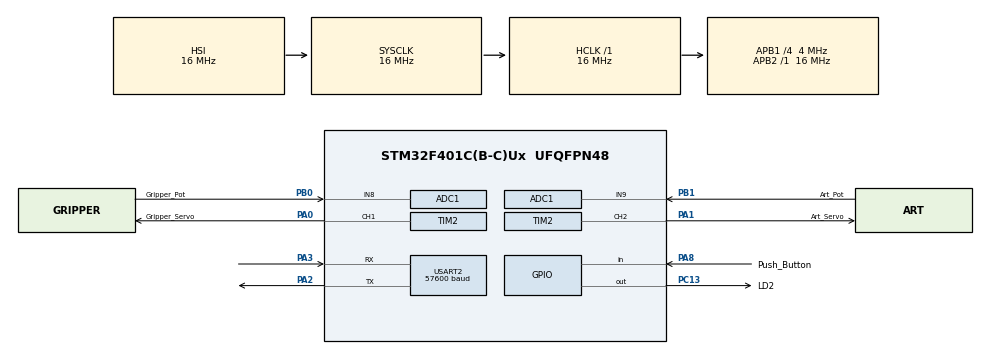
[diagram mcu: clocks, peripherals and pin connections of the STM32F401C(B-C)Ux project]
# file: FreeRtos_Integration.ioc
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ADC1.Channel-0\#ChannelRegularConversion=ADC_CHANNEL_8
ADC1.Channel-1\#ChannelRegularConversion=ADC_CHANNEL_9
ADC1.ContinuousConvMode=ENABLE
ADC1.NbrOfConversion=2
ADC1.NbrOfConversionFlag=1
ADC1.Rank-0\#ChannelRegularConversion=1
ADC1.Rank-1\#ChannelRegularConversion=2
ADC1.SamplingTime-0\#ChannelRegularConversion=ADC_SAMPLETIME_480CYCLES
ADC1.SamplingTime-1\#ChannelRegularConversion=ADC_SAMPLETIME_480CYCLES
ADC1.ScanConvMode=ENABLE
ADC1.master=1
Dma.ADC1.0.Direction=DMA_PERIPH_TO_MEMORY
Dma.ADC1.0.FIFOMode=DMA_FIFOMODE_DISABLE
Dma.ADC1.0.Instance=DMA2_Stream0
Dma.ADC1.0.MemDataAlignment=DMA_MDATAALIGN_HALFWORD
Dma.ADC1.0.MemInc=DMA_MINC_ENABLE
Dma.ADC1.0.Mode=DMA_NORMAL
Dma.ADC1.0.PeriphDataAlignment=DMA_PDATAALIGN_HALFWORD
Dma.ADC1.0.PeriphInc=DMA_PINC_DISABLE
Dma.ADC1.0.Priority=DMA_PRIORITY_LOW
Dma.Request0=ADC1
Dma.Request1=USART2_RX
Dma.Request2=USART2_TX
Dma.USART2_RX.1.Direction=DMA_PERIPH_TO_MEMORY
Dma.USART2_RX.1.FIFOMode=DMA_FIFOMODE_DISABLE
Dma.USART2_RX.1.Instance=DMA1_Stream5
Dma.USART2_RX.1.MemDataAlignment=DMA_MDATAALIGN_BYTE
Dma.USART2_RX.1.MemInc=DMA_MINC_ENABLE
Dma.USART2_RX.1.Mode=DMA_NORMAL
Dma.USART2_RX.1.PeriphDataAlignment=DMA_PDATAALIGN_BYTE
Dma.USART2_RX.1.PeriphInc=DMA_PINC_DISABLE
Dma.USART2_RX.1.Priority=DMA_PRIORITY_LOW
Dma.USART2_TX.2.Direction=DMA_MEMORY_TO_PERIPH
Dma.USART2_TX.2.FIFOMode=DMA_FIFOMODE_DISABLE
Dma.USART2_TX.2.Instance=DMA1_Stream6
Dma.USART2_TX.2.MemDataAlignment=DMA_MDATAALIGN_BYTE
Dma.USART2_TX.2.MemInc=DMA_MINC_ENABLE
Dma.USART2_TX.2.Mode=DMA_NORMAL
Dma.USART2_TX.2.PeriphDataAlignment=DMA_PDATAALIGN_BYTE
Dma.USART2_TX.2.PeriphInc=DMA_PINC_DISABLE
Dma.USART2_TX.2.Priority=DMA_PRIORITY_LOW
FREERTOS.Tasks01=TaskADC,24,128,StartTaskADC,Default,NULL,Dynamic,NULL,NULL;GripperOpenTask,25,128,StartGripperOpenTask,Default,NULL,Dynamic,NULL,NULL;GripperClose,26,128,StartGripperCloseTask,Default,NULL,Dynamic,NULL,NULL;GripperGoToTask,27,128,StartGripperGoToTask,Default,NULL,Dynamic,NULL,NULL;TaskRosserial,40,128,StartTaskRosserial,Default,NULL,Dynamic,NULL,NULL;ButtonTask,8,128,StartButtonTask,Default,NULL,Dynamic,NULL,NULL;ArtUpTask,28,128,StartArtUpTask,Default,NULL,Dynamic,NULL,NULL;ArtDownTask,29,128,StartArtDownTask,Default,NULL,Dynamic,NULL,NULL;ArtGoToTask,30,128,StartArtGoToTask,Default,NULL,Dynamic,NULL,NULL
FREERTOS.configUSE_NEWLIB_REENTRANT=1
Mcu.Family=STM32F4
Mcu.Name=STM32F401C(B-C)Ux
Mcu.Package=UFQFPN48
NVIC.DMA1_Stream5_IRQn=true\:5\:0\:false\:false\:true\:true\:false\:true\:true
NVIC.DMA1_Stream6_IRQn=true\:5\:0\:false\:false\:true\:true\:false\:true\:true
NVIC.DMA2_Stream0_IRQn=true\:5\:0\:false\:false\:true\:true\:false\:true\:true
NVIC.PriorityGroup=NVIC_PRIORITYGROUP_4
NVIC.TIM5_IRQn=true\:15\:0\:false\:false\:true\:false\:false\:true\:true
NVIC.TimeBase=TIM5_IRQn
NVIC.TimeBaseIP=TIM5
NVIC.USART2_IRQn=true\:5\:0\:false\:false\:true\:true\:true\:true\:true
PA0-WKUP.GPIO_Label=Gripper_Servo
PA0-WKUP.Signal=S_TIM2_CH1_ETR
PA1.GPIO_Label=Art_Servo
PA1.Signal=S_TIM2_CH2
PA2.Mode=Asynchronous
PA2.Signal=USART2_TX
PA3.Mode=Asynchronous
PA3.Signal=USART2_RX
PA8.GPIO_Label=Push_Button
PA8.Signal=GPIO_Input
PB0.GPIO_Label=Gripper_Pot
PB0.Signal=ADCx_IN8
PB1.GPIO_Label=Art_Pot
PB1.Signal=ADCx_IN9
PC13-ANTI_TAMP.GPIO_Label=LD2
PC13-ANTI_TAMP.Signal=GPIO_Output
ProjectManager.HeapSize=0x200
ProjectManager.StackSize=0x400
ProjectManager.TargetToolchain=STM32CubeIDE
RCC.AHBFreq_Value=16000000
RCC.APB1CLKDivider=RCC_HCLK_DIV4
RCC.APB1Freq_Value=4000000
RCC.APB1TimFreq_Value=8000000
RCC.APB2Freq_Value=16000000
RCC.CortexFreq_Value=16000000
RCC.HSE_VALUE=25000000
RCC.HSI_VALUE=16000000
RCC.LSE_VALUE=32768
RCC.SYSCLKFreq_VALUE=16000000
RCC.VCOOutputFreq_Value=192000000
SH.ADCx_IN8.0=ADC1_IN8,IN8
SH.ADCx_IN9.0=ADC1_IN9,IN9
SH.S_TIM2_CH1_ETR.0=TIM2_CH1,PWM Generation1 CH1
SH.S_TIM2_CH2.0=TIM2_CH2,PWM Generation2 CH2
TIM2.Channel-PWM\ Generation1\ CH1=TIM_CHANNEL_1
TIM2.Channel-PWM\ Generation2\ CH2=TIM_CHANNEL_2
TIM2.Period=2499
TIM2.Prescaler=64
USART2.BaudRate=57600
USART2.VirtualMode=VM_ASYNC
VP_FREERTOS_VS_CMSIS_V2.Mode=CMSIS_V2
VP_SYS_VS_tim5.Mode=TIM5
VP_TIM2_VS_ClockSourceINT.Mode=Internal
board=custom

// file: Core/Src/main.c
/* USER CODE BEGIN Header */
/**
  ******************************************************************************
  * @file           : main.c
  * @brief          : Main program body
  ******************************************************************************
  * @attention
  *
  * Copyright (c) 2023 STMicroelectronics.
  * All rights reserved.
  *
  * This software is licensed under terms that can be found in the LICENSE file
  * in the root directory of this software component.
  * If no LICENSE file comes with this software, it is provided AS-IS.
  *
  ******************************************************************************
  */
/* USER CODE END Header */
#include "main.h"
#include "cmsis_os.h"

/* USER CODE BEGIN Includes */
#include "mainpp.h"
/* USER CODE END Includes */

/* USER CODE BEGIN PD */
#define GRIPPER_OPENED_ANG = 0;
#define GRIPPER_CLOSED_ANG = 105;
#define ART_DOWN_ANG = 0;
#define ART_UP_ANG = 90;
/* USER CODE END PD */

ADC_HandleTypeDef hadc1;
DMA_HandleTypeDef hdma_adc1;

TIM_HandleTypeDef htim2;

UART_HandleTypeDef huart2;
DMA_HandleTypeDef hdma_usart2_rx;
DMA_HandleTypeDef hdma_usart2_tx;

/* Definitions for TaskADC */
osThreadId_t TaskADCHandle;
const osThreadAttr_t TaskADC_attributes = {
  .name = "TaskADC",
  .stack_size = 128 * 4,
  .priority = (osPriority_t) osPriorityAboveNormal,
};
/* Definitions for GripperOpenTask */
osThreadId_t GripperOpenTaskHandle;
const osThreadAttr_t GripperOpenTask_attributes = {
  .name = "GripperOpenTask",
  .stack_size = 128 * 4,
  .priority = (osPriority_t) osPriorityNormal,
};
/* Definitions for GripperClose */
osThreadId_t GripperCloseHandle;
const osThreadAttr_t GripperClose_attributes = {
  .name = "GripperClose",
  .stack_size = 128 * 4,
  .priority = (osPriority_t) osPriorityNormal,
};
/* Definitions for GripperGoToTask */
osThreadId_t GripperGoToTaskHandle;
const osThreadAttr_t GripperGoToTask_attributes = {
  .name = "GripperGoToTask",
  .stack_size = 128 * 4,
  .priority = (osPriority_t) osPriorityNormal,
};
/* Definitions for TaskRosserial */
osThreadId_t TaskRosserialHandle;
const osThreadAttr_t TaskRosserial_attributes = {
  .name = "TaskRosserial",
  .stack_size = 128 * 4,
  .priority = (osPriority_t) osPriorityHigh,
};
/* USER CODE BEGIN PV */
// ADC Variables & constants
int adc1, adc2;
int ang[2];
volatile uint16_t adc_result[2];
const int adc_channel_count = sizeof(adc_result) / sizeof(adc_result[0]);

// Flags
int gripper_instruction_flag = 0;
int art_instruction_flag = 0;
int gripper_ang_response = 0;
int art_ang_response = 0;
int button_pressed = 0;
int emergency_stop = 0;

// Servo constants

/* USER CODE END PV */

void SystemClock_Config(void);
static void MX_GPIO_Init(void);
static void MX_DMA_Init(void);
static void MX_ADC1_Init(void);
static void MX_TIM2_Init(void);
static void MX_USART2_UART_Init(void);
void StartTaskADC(void *argument);
void StartGripperOpenTask(void *argument);
void StartGripperClose(void *argument);
void StartGripperGoToTask(void *argument);
void StartTaskRosserial(void *argument);

int main(void)
{

  /* MCU Configuration--------------------------------------------------------*/

  /* Reset of all peripherals, Initializes the Flash interface and the Systick. */
  HAL_Init();

  /* Configure the system clock */
  SystemClock_Config();

  /* Initialize all configured peripherals */
  MX_GPIO_Init();
  MX_DMA_Init();
  MX_ADC1_Init();
  MX_TIM2_Init();
  MX_USART2_UART_Init();
  /* USER CODE BEGIN 2 */
  HAL_TIM_PWM_Start(&htim2, TIM_CHANNEL_1);
  HAL_TIM_PWM_Start(&htim2, TIM_CHANNEL_2);
  setup();
  TIM2->CCR1 = 60;
  TIM2->CCR2 = 60;
  /* USER CODE END 2 */

  /* Init scheduler */
  osKernelInitialize();

  /* Create the thread(s) */
  /* creation of TaskADC */
  TaskADCHandle = osThreadNew(StartTaskADC, NULL, &TaskADC_attributes);

  /* creation of GripperOpenTask */
  GripperOpenTaskHandle = osThreadNew(StartGripperOpenTask, NULL, &GripperOpenTask_attributes);

  /* creation of GripperClose */
  GripperCloseHandle = osThreadNew(StartGripperClose, NULL, &GripperClose_attributes);

  /* creation of GripperGoToTask */
  GripperGoToTaskHandle = osThreadNew(StartGripperGoToTask, NULL, &GripperGoToTask_attributes);

  /* creation of TaskRosserial */
  TaskRosserialHandle = osThreadNew(StartTaskRosserial, NULL, &TaskRosserial_attributes);

  /* Start scheduler */
  osKernelStart();
  /* We should never get here as control is now taken by the scheduler */
  /* Infinite loop */
  while (1)
  {

  }
}

void SystemClock_Config(void)
{
  RCC_OscInitTypeDef RCC_OscInitStruct = {0};
  RCC_ClkInitTypeDef RCC_ClkInitStruct = {0};

  /** Configure the main internal regulator output voltage
  */
  __HAL_RCC_PWR_CLK_ENABLE();
  __HAL_PWR_VOLTAGESCALING_CONFIG(PWR_REGULATOR_VOLTAGE_SCALE2);

  /** Initializes the RCC Oscillators according to the specified parameters
  * in the RCC_OscInitTypeDef structure.
  */
  RCC_OscInitStruct.OscillatorType = RCC_OSCILLATORTYPE_HSI;
  RCC_OscInitStruct.HSIState = RCC_HSI_ON;
  RCC_OscInitStruct.HSICalibrationValue = RCC_HSICALIBRATION_DEFAULT;
  RCC_OscInitStruct.PLL.PLLState = RCC_PLL_NONE;
  if (HAL_RCC_OscConfig(&RCC_OscInitStruct) != HAL_OK)
  {
    Error_Handler();
  }

  /** Initializes the CPU, AHB and APB buses clocks
  */
  RCC_ClkInitStruct.ClockType = RCC_CLOCKTYPE_HCLK|RCC_CLOCKTYPE_SYSCLK
                              |RCC_CLOCKTYPE_PCLK1|RCC_CLOCKTYPE_PCLK2;
  RCC_ClkInitStruct.SYSCLKSource = RCC_SYSCLKSOURCE_HSI;
  RCC_ClkInitStruct.AHBCLKDivider = RCC_SYSCLK_DIV1;
  RCC_ClkInitStruct.APB1CLKDivider = RCC_HCLK_DIV4;
  RCC_ClkInitStruct.APB2CLKDivider = RCC_HCLK_DIV1;

  if (HAL_RCC_ClockConfig(&RCC_ClkInitStruct, FLASH_LATENCY_0) != HAL_OK)
  {
    Error_Handler();
  }
}

static void MX_ADC1_Init(void)
{

  ADC_ChannelConfTypeDef sConfig = {0};

  /** Configure the global features of the ADC (Clock, Resolution, Data Alignment and number of conversion)
  */
  hadc1.Instance = ADC1;
  hadc1.Init.ClockPrescaler = ADC_CLOCK_SYNC_PCLK_DIV2;
  hadc1.Init.Resolution = ADC_RESOLUTION_12B;
  hadc1.Init.ScanConvMode = ENABLE;
  hadc1.Init.ContinuousConvMode = ENABLE;
  hadc1.Init.DiscontinuousConvMode = DISABLE;
  hadc1.Init.ExternalTrigConvEdge = ADC_EXTERNALTRIGCONVEDGE_NONE;
  hadc1.Init.ExternalTrigConv = ADC_SOFTWARE_START;
  hadc1.Init.DataAlign = ADC_DATAALIGN_RIGHT;
  hadc1.Init.NbrOfConversion = 2;
  hadc1.Init.DMAContinuousRequests = DISABLE;
  hadc1.Init.EOCSelection = ADC_EOC_SINGLE_CONV;
  if (HAL_ADC_Init(&hadc1) != HAL_OK)
  {
    Error_Handler();
  }

  /** Configure for the selected ADC regular channel its corresponding rank in the sequencer and its sample time.
  */
  sConfig.Channel = ADC_CHANNEL_8;
  sConfig.Rank = 1;
  sConfig.SamplingTime = ADC_SAMPLETIME_480CYCLES;
  if (HAL_ADC_ConfigChannel(&hadc1, &sConfig) != HAL_OK)
  {
    Error_Handler();
  }

  /** Configure for the selected ADC regular channel its corresponding rank in the sequencer and its sample time.
  */
  sConfig.Channel = ADC_CHANNEL_9;
  sConfig.Rank = 2;
  if (HAL_ADC_ConfigChannel(&hadc1, &sConfig) != HAL_OK)
  {
    Error_Handler();
  }

}

static void MX_TIM2_Init(void)
{

  TIM_ClockConfigTypeDef sClockSourceConfig = {0};
  TIM_MasterConfigTypeDef sMasterConfig = {0};
  TIM_OC_InitTypeDef sConfigOC = {0};

  htim2.Instance = TIM2;
  htim2.Init.Prescaler = 64;
  htim2.Init.CounterMode = TIM_COUNTERMODE_UP;
  htim2.Init.Period = 2499;
  htim2.Init.ClockDivision = TIM_CLOCKDIVISION_DIV1;
  htim2.Init.AutoReloadPreload = TIM_AUTORELOAD_PRELOAD_DISABLE;
  if (HAL_TIM_Base_Init(&htim2) != HAL_OK)
  {
    Error_Handler();
  }
  sClockSourceConfig.ClockSource = TIM_CLOCKSOURCE_INTERNAL;
  if (HAL_TIM_ConfigClockSource(&htim2, &sClockSourceConfig) != HAL_OK)
  {
    Error_Handler();
  }
  if (HAL_TIM_PWM_Init(&htim2) != HAL_OK)
  {
    Error_Handler();
  }
  sMasterConfig.MasterOutputTrigger = TIM_TRGO_RESET;
  sMasterConfig.MasterSlaveMode = TIM_MASTERSLAVEMODE_DISABLE;
  if (HAL_TIMEx_MasterConfigSynchronization(&htim2, &sMasterConfig) != HAL_OK)
  {
    Error_Handler();
  }
  sConfigOC.OCMode = TIM_OCMODE_PWM1;
  sConfigOC.Pulse = 0;
  sConfigOC.OCPolarity = TIM_OCPOLARITY_HIGH;
  sConfigOC.OCFastMode = TIM_OCFAST_DISABLE;
  if (HAL_TIM_PWM_ConfigChannel(&htim2, &sConfigOC, TIM_CHANNEL_1) != HAL_OK)
  {
    Error_Handler();
  }
  if (HAL_TIM_PWM_ConfigChannel(&htim2, &sConfigOC, TIM_CHANNEL_2) != HAL_OK)
  {
    Error_Handler();
  }
  HAL_TIM_MspPostInit(&htim2);

}

static void MX_USART2_UART_Init(void)
{

  huart2.Instance = USART2;
  huart2.Init.BaudRate = 57600;
  huart2.Init.WordLength = UART_WORDLENGTH_8B;
  huart2.Init.StopBits = UART_STOPBITS_1;
  huart2.Init.Parity = UART_PARITY_NONE;
  huart2.Init.Mode = UART_MODE_TX_RX;
  huart2.Init.HwFlowCtl = UART_HWCONTROL_NONE;
  huart2.Init.OverSampling = UART_OVERSAMPLING_16;
  if (HAL_UART_Init(&huart2) != HAL_OK)
  {
    Error_Handler();
  }

}

static void MX_DMA_Init(void)
{

  /* DMA controller clock enable */
  __HAL_RCC_DMA2_CLK_ENABLE();
  __HAL_RCC_DMA1_CLK_ENABLE();

  /* DMA interrupt init */
  /* DMA1_Stream5_IRQn interrupt configuration */
  HAL_NVIC_SetPriority(DMA1_Stream5_IRQn, 5, 0);
  HAL_NVIC_EnableIRQ(DMA1_Stream5_IRQn);
  /* DMA1_Stream6_IRQn interrupt configuration */
  HAL_NVIC_SetPriority(DMA1_Stream6_IRQn, 5, 0);
  HAL_NVIC_EnableIRQ(DMA1_Stream6_IRQn);
  /* DMA2_Stream0_IRQn interrupt configuration */
  HAL_NVIC_SetPriority(DMA2_Stream0_IRQn, 5, 0);
  HAL_NVIC_EnableIRQ(DMA2_Stream0_IRQn);

}

static void MX_GPIO_Init(void)
{
  GPIO_InitTypeDef GPIO_InitStruct = {0};

  /* GPIO Ports Clock Enable */
  __HAL_RCC_GPIOC_CLK_ENABLE();
  __HAL_RCC_GPIOA_CLK_ENABLE();
  __HAL_RCC_GPIOB_CLK_ENABLE();

  /*Configure GPIO pin Output Level */
  HAL_GPIO_WritePin(LD2_GPIO_Port, LD2_Pin, GPIO_PIN_RESET);

  /*Configure GPIO pin : LD2_Pin */
  GPIO_InitStruct.Pin = LD2_Pin;
  GPIO_InitStruct.Mode = GPIO_MODE_OUTPUT_PP;
  GPIO_InitStruct.Pull = GPIO_NOPULL;
  GPIO_InitStruct.Speed = GPIO_SPEED_FREQ_LOW;
  HAL_GPIO_Init(LD2_GPIO_Port, &GPIO_InitStruct);

  /*Configure GPIO pin : PA6 */
  GPIO_InitStruct.Pin = GPIO_PIN_6;
  GPIO_InitStruct.Mode = GPIO_MODE_INPUT;
  GPIO_InitStruct.Pull = GPIO_NOPULL;
  HAL_GPIO_Init(GPIOA, &GPIO_InitStruct);

}

/* USER CODE BEGIN 4 */
int get_servo_pos_liveExpression(int n){
	if (n == 1) {
		return TIM2->CCR1;
	}
	else if (n == 2) {
		return TIM2->CCR2;
	}
	return 0;
}
float pwm_to_ang(int n){
	if (n == 1){
		return (180.0/240.0)*((float)TIM2->CCR1 - 60);
	}
	if(n == 2){
		return (180.0/240.0)*((float)TIM2->CCR2 - 60);
	}
	return -1;
}
void move_servo_to(int n, int pwm){
	if (n == 1){
		TIM2->CCR1 = pwm;
	}
	else if(n == 2){
		TIM2->CCR2 = pwm;
	}
}
void move_servo_fw(int n){
	if (n == 1){
		TIM2->CCR1 += 1;
	}
	else if(n == 2){
		TIM2->CCR2 += 1;
	}
}
void move_servo_bw(int n){
	if (n == 1){
		TIM2->CCR1 -= 1;
	}
	else if(n == 2){
		TIM2->CCR2 -= 1;
	}
}
/* USER CODE END 4 */

void StartTaskADC(void *argument)
{
  /* USER CODE BEGIN 5 */
  /* Infinite loop */
  for(;;)
  {
	  HAL_ADC_Start_DMA(&hadc1, (uint32_t*)adc_result, adc_channel_count);
	  osDelay(100);
  }
  /* USER CODE END 5 */
}

void StartGripperOpenTask(void *argument)
{
  /* USER CODE BEGIN StartGripperOpenTask */
  /* Infinite loop */
	for(;;)
	{
		if (emergency_stop == 0 && gripper_instruction_flag != 0){
			if (gripper_instruction_flag == 1){
				while(ang[0] < 160){
					move_servo_fw(1);
					ang[0] = pwm_to_ang(1);
					osDelay(50);
				}
			}
			else if(gripper_instruction_flag == 2){
				while(ang[0] < 160){
					move_servo_bw(1);
					ang[0] = pwm_to_ang(1);
					osDelay(50);
				}
			}
		}
		else{
  		  osDelay(200);
		}
    }
    osThreadTerminate(NULL);
  /* USER CODE END StartGripperOpenTask */
}

void StartGripperClose(void *argument)
{
  /* USER CODE BEGIN StartGripperClose */
  /* Infinite loop */
  for(;;)
  {
    osDelay(10000);
  }
  osThreadTerminate(NULL);

  /* USER CODE END StartGripperClose */
}

void StartGripperGoToTask(void *argument)
{
  /* USER CODE BEGIN StartGripperGoToTask */
  /* Infinite loop */
  for(;;)
  {
    osDelay(1);
  }
  osThreadTerminate(NULL);
  /* USER CODE END StartGripperGoToTask */
}

void StartTaskRosserial(void *argument)
{
  /* USER CODE BEGIN StartTaskRosserial */
  /* Infinite loop */
  for(;;)
  {
	loop();
    osDelay(1000);
  }
  osThreadTerminate(NULL);
  /* USER CODE END StartTaskRosserial */
}

void HAL_TIM_PeriodElapsedCallback(TIM_HandleTypeDef *htim)
{
  if (htim->Instance == TIM5) {
    HAL_IncTick();
  }
}

void Error_Handler(void)
{
  __disable_irq();
  while (1)
  {
  }
}
